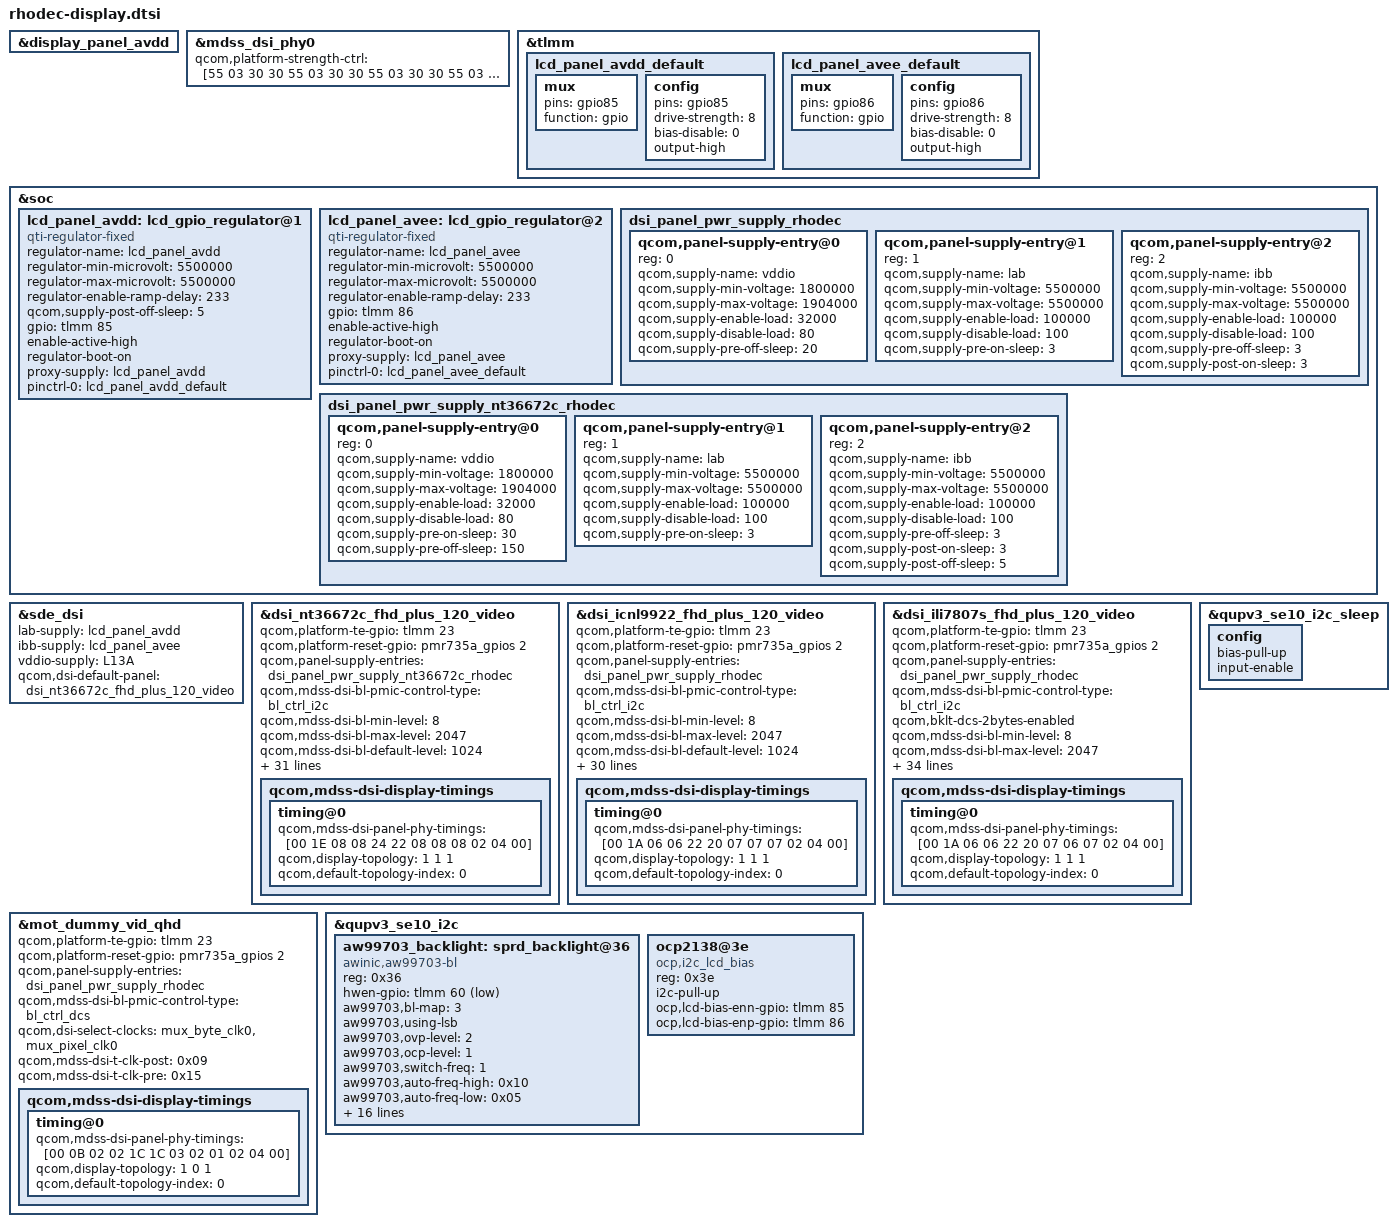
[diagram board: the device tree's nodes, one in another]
#include "dsi-panel-mot-dummy-qhd-video.dtsi"
#include "dsi-panel-mot-tianma-nt36672c-645-1080x2400-video.dtsi"
#include "dsi-panel-mot-txd-ili7807s-645-1080x2400-video.dtsi"
#include "dsi-panel-mot-tianma-icnl9922-645-1080x2400-video.dtsi"

&display_panel_avdd {
	/delete-property/ gpio;
	/delete-property/ pinctrl-0;
};

&mdss_dsi_phy0 {
	qcom,platform-strength-ctrl = [55 03 30 30
				55 03 30 30
				55 03 30 30
				55 03 30 30
				55 00 30 30];
};

&tlmm {
	lcd_panel_avdd_default: lcd_panel_avdd_default {
		mux {
			pins = "gpio85";
			function = "gpio";
		};

		config {
			pins = "gpio85";
			drive-strength = <8>;
			bias-disable = <0>;
			output-high;
		};
	};

	lcd_panel_avee_default: lcd_panel_avee_default {
		mux {
			pins = "gpio86";
			function = "gpio";
		};

		config {
			pins = "gpio86";
			drive-strength = <8>;
			bias-disable = <0>;
			output-high;
		};
	};
};

&soc {
	lcd_panel_avdd: lcd_gpio_regulator@1 {
		compatible = "qti-regulator-fixed";
		regulator-name = "lcd_panel_avdd";
		regulator-min-microvolt = <5500000>;
		regulator-max-microvolt = <5500000>;
		regulator-enable-ramp-delay = <233>;
		qcom,supply-post-off-sleep = <5>;
		gpio = <&tlmm 85 0>;
		enable-active-high;
		regulator-boot-on;
		proxy-supply = <&lcd_panel_avdd>;
		pinctrl-names = "default";
		pinctrl-0 = <&lcd_panel_avdd_default>;
	};

	lcd_panel_avee: lcd_gpio_regulator@2 {
		compatible = "qti-regulator-fixed";
		regulator-name = "lcd_panel_avee";
		regulator-min-microvolt = <5500000>;
		regulator-max-microvolt = <5500000>;
		regulator-enable-ramp-delay = <233>;
		gpio = <&tlmm 86 0>;
		enable-active-high;
		regulator-boot-on;
		proxy-supply = <&lcd_panel_avee>;
		pinctrl-names = "default";
		pinctrl-0 = <&lcd_panel_avee_default>;
	};
};

&sde_dsi {
	/delete-property/ lab-supply;
	/delete-property/ ibb-supply;
	/delete-property/ vddio-supply;
	/delete-property/ qcom,dsi-default-panel;
	/delete-property/ avdd-supply;

	lab-supply = <&lcd_panel_avdd>;
	ibb-supply = <&lcd_panel_avee>;
	vddio-supply = <&L13A>;

	qcom,dsi-default-panel = <&dsi_nt36672c_fhd_plus_120_video>;
};

&soc {
	dsi_panel_pwr_supply_rhodec: dsi_panel_pwr_supply_rhodec{
		#address-cells = <1>;
		#size-cells = <0>;

		qcom,panel-supply-entry@0 {
			reg = <0>;
			qcom,supply-name = "vddio";
			qcom,supply-min-voltage = <1800000>;
			qcom,supply-max-voltage = <1904000>;
			qcom,supply-enable-load = <32000>;
			qcom,supply-disable-load = <80>;
			qcom,supply-pre-off-sleep = <20>;
		};

		qcom,panel-supply-entry@1 {
			reg = <1>;
			qcom,supply-name = "lab";
			qcom,supply-min-voltage = <5500000>;
			qcom,supply-max-voltage = <5500000>;
			qcom,supply-enable-load = <100000>;
			qcom,supply-disable-load = <100>;
			qcom,supply-pre-on-sleep = <3>;
		};

		qcom,panel-supply-entry@2 {
			reg = <2>;
			qcom,supply-name = "ibb";
			qcom,supply-min-voltage = <5500000>;
			qcom,supply-max-voltage = <5500000>;
			qcom,supply-enable-load = <100000>;
			qcom,supply-disable-load = <100>;
			qcom,supply-pre-off-sleep = <3>;
			qcom,supply-post-on-sleep = <3>;
		};

	};
};

&soc {
	dsi_panel_pwr_supply_nt36672c_rhodec: dsi_panel_pwr_supply_nt36672c_rhodec{
		#address-cells = <1>;
		#size-cells = <0>;

		qcom,panel-supply-entry@0 {
			reg = <0>;
			qcom,supply-name = "vddio";
			qcom,supply-min-voltage = <1800000>;
			qcom,supply-max-voltage = <1904000>;
			qcom,supply-enable-load = <32000>;
			qcom,supply-disable-load = <80>;
			qcom,supply-pre-on-sleep = <30>;
			qcom,supply-pre-off-sleep = <150>;
		};

		qcom,panel-supply-entry@1 {
			reg = <1>;
			qcom,supply-name = "lab";
			qcom,supply-min-voltage = <5500000>;
			qcom,supply-max-voltage = <5500000>;
			qcom,supply-enable-load = <100000>;
			qcom,supply-disable-load = <100>;
			qcom,supply-pre-on-sleep = <3>;
		};

		qcom,panel-supply-entry@2 {
			reg = <2>;
			qcom,supply-name = "ibb";
			qcom,supply-min-voltage = <5500000>;
			qcom,supply-max-voltage = <5500000>;
			qcom,supply-enable-load = <100000>;
			qcom,supply-disable-load = <100>;
			qcom,supply-pre-off-sleep = <3>;
			qcom,supply-post-on-sleep = <3>;
			qcom,supply-post-off-sleep = <5>;
		};

	};
};

&dsi_nt36672c_fhd_plus_120_video {
	qcom,platform-te-gpio = <&tlmm 23 0>;
	qcom,platform-reset-gpio = <&pmr735a_gpios 2 0>;

	qcom,panel-supply-entries = <&dsi_panel_pwr_supply_nt36672c_rhodec>;
	qcom,mdss-dsi-bl-pmic-control-type = "bl_ctrl_i2c";
	qcom,mdss-dsi-bl-min-level = <8>;
	qcom,mdss-dsi-bl-max-level = <2047>;
	qcom,mdss-dsi-bl-default-level = <1024>;
	qcom,mdss-brightness-max-level = <2047>;
	qcom,mdss-dsi-no-panel-on-read-support;
	qcom,mdss-dsi-panel-supplier = "tm";

	qcom,esd-check-enabled;
	qcom,mdss-dsi-panel-status-check-mode = "reg_read";
	qcom,mdss-dsi-panel-status-command = [06 01 00 01 00 00 01 0a];
	qcom,mdss-dsi-panel-status-command-state = "dsi_lp_mode";
	qcom,mdss-dsi-panel-status-value = <0x9c>;
	qcom,mdss-dsi-panel-on-check-value = <0x9c>;
	qcom,mdss-dsi-panel-status-read-length = <1>;

	qcom,tp_state_check_enable;

	qcom,dsi-supported-dfps-list = <120 90 60>;
	qcom,mdss-dsi-pan-enable-dynamic-fps;
	qcom,mdss-dsi-pan-fps-update = "dfps_immediate_porch_mode_vfp";

	qcom,mdss-dsi-hbm-on-command = [39 01 00 00 00 00 03 51 07 FF];
	qcom,mdss-dsi-hbm-on-command-state =  "dsi_lp_mode";
	qcom,mdss-dsi-hbm-off-command = [39 01 00 00 00 00 03 51 06 66];
	qcom,mdss-dsi-hbm-off-command-state =  "dsi_lp_mode";
	qcom,mdss-dsi-hbm-type = "lcd-dcs-wled";

	qcom,dsi-select-clocks = "mux_byte_clk0", "mux_pixel_clk0";
	qcom,mdss-dsi-t-clk-post = <0x0D>;
	qcom,mdss-dsi-t-clk-pre = <0x34>;
	qcom,mdss-dsi-display-timings {
		timing@0 {
			qcom,mdss-dsi-panel-phy-timings = [00 1E 08 08 24 22 08 08 08 02 04 00];
			qcom,display-topology = <1 1 1>;
			qcom,default-topology-index = <0>;
		};
	};
};



&dsi_icnl9922_fhd_plus_120_video {
        qcom,platform-te-gpio = <&tlmm 23 0>;
        qcom,platform-reset-gpio = <&pmr735a_gpios 2 0>;

        qcom,panel-supply-entries = <&dsi_panel_pwr_supply_rhodec>;
        qcom,mdss-dsi-bl-pmic-control-type = "bl_ctrl_i2c";
        qcom,mdss-dsi-bl-min-level = <8>;
        qcom,mdss-dsi-bl-max-level = <2047>;
        qcom,mdss-dsi-bl-default-level = <1024>;
        qcom,mdss-brightness-max-level = <2047>;
        qcom,mdss-dsi-no-panel-on-read-support;

        qcom,esd-check-enabled;
        qcom,mdss-dsi-panel-status-check-mode = "reg_read";
        qcom,mdss-dsi-panel-status-command = [06 01 00 01 00 00 01 0a];
        qcom,mdss-dsi-panel-status-command-state = "dsi_lp_mode";
        qcom,mdss-dsi-panel-status-value = <0x9c>;
        qcom,mdss-dsi-panel-on-check-value = <0x9c>;
        qcom,mdss-dsi-panel-status-read-length = <1>;

        qcom,tp_state_check_enable;

        qcom,dsi-supported-dfps-list = <120 90 60>;
        qcom,mdss-dsi-pan-enable-dynamic-fps;
        qcom,mdss-dsi-pan-fps-update = "dfps_immediate_porch_mode_vfp";

        qcom,mdss-dsi-hbm-on-command = [15 01 00 00 00 00 02 51 FF];
        qcom,mdss-dsi-hbm-on-command-state =  "dsi_lp_mode";
        qcom,mdss-dsi-hbm-off-command = [15 01 00 00 00 00 02 51 CC];
        qcom,mdss-dsi-hbm-off-command-state =  "dsi_lp_mode";
        qcom,mdss-dsi-hbm-type = "lcd-dcs-wled";

        qcom,dsi-select-clocks = "mux_byte_clk0", "mux_pixel_clk0";
        qcom,mdss-dsi-t-clk-post = <0x0E>;
        qcom,mdss-dsi-t-clk-pre = <0x39>;
        qcom,mdss-dsi-display-timings {
                timing@0 {
                        qcom,mdss-dsi-panel-phy-timings = [00 1A 06 06 22 20 07 07 07 02 04 00];
                        qcom,display-topology = <1 1 1>;
                        qcom,default-topology-index = <0>;
                };
        };
};

&dsi_ili7807s_fhd_plus_120_video {
	qcom,platform-te-gpio = <&tlmm 23 0>;
	qcom,platform-reset-gpio = <&pmr735a_gpios 2 0>;

	qcom,panel-supply-entries = <&dsi_panel_pwr_supply_rhodec>;
	qcom,mdss-dsi-bl-pmic-control-type = "bl_ctrl_i2c";
	qcom,bklt-dcs-2bytes-enabled;

	qcom,mdss-dsi-bl-min-level = <8>;
	qcom,mdss-dsi-bl-max-level = <2047>;
	qcom,mdss-dsi-bl-default-level = <1024>;
	qcom,mdss-brightness-max-level = <2047>;

	qcom,esd-check-enabled;
	qcom,mdss-dsi-panel-status-check-mode = "reg_read";
	qcom,mdss-dsi-panel-status-command = [06 01 00 01 00 00 01 0a];
	qcom,mdss-dsi-panel-status-command-state = "dsi_lp_mode";
	qcom,mdss-dsi-panel-status-value = <0x9c>;
	qcom,mdss-dsi-panel-on-check-value = <0x9c>;
	qcom,mdss-dsi-panel-status-read-length = <1>;
	qcom,mdss-dsi-no-panel-on-read-support;
	qcom,mdss-dsi-panel-supplier = "txd";

	qcom,mdss-dsi-hbm-on-command = [39 01 00 00 00 00 03 51 07 FF];
	qcom,mdss-dsi-hbm-on-command-state =  "dsi_lp_mode";
	qcom,mdss-dsi-hbm-off-command = [39 01 00 00 00 00 03 51 06 66];
	qcom,mdss-dsi-hbm-off-command-state =  "dsi_lp_mode";
        qcom,mdss-dsi-hbm-type = "lcd-dcs-wled";

	qcom,suspend-ulps-enabled;

	qcom,tp_state_check_enable;
	qcom,platform-need-execute-shutdown;

	qcom,mdss-dsi-pan-enable-dynamic-fps;
	qcom,mdss-dsi-pan-fps-update = "dfps_immediate_porch_mode_vfp";
	qcom,dsi-supported-dfps-list = <120 90 60>;

	qcom,dsi-select-clocks = "mux_byte_clk0", "mux_pixel_clk0";
	qcom,mdss-dsi-t-clk-post = <0x0C>;
	qcom,mdss-dsi-t-clk-pre = <0x2F>;
	qcom,mdss-dsi-display-timings {
		timing@0 {
			qcom,mdss-dsi-panel-phy-timings = [00 1A 06 06 22 20 07
				06 07 02 04 00];
			qcom,display-topology = <1 1 1>;
			qcom,default-topology-index = <0>;
		};
	};
};

&mot_dummy_vid_qhd {
	qcom,platform-te-gpio = <&tlmm 23 0>;
	qcom,platform-reset-gpio = <&pmr735a_gpios 2 0>;

	qcom,panel-supply-entries = <&dsi_panel_pwr_supply_rhodec>;

	qcom,mdss-dsi-bl-pmic-control-type = "bl_ctrl_dcs";

	qcom,dsi-select-clocks = "mux_byte_clk0", "mux_pixel_clk0";
	qcom,mdss-dsi-t-clk-post = <0x09>;
	qcom,mdss-dsi-t-clk-pre = <0x15>;
	qcom,mdss-dsi-display-timings {
		timing@0 {
			qcom,mdss-dsi-panel-phy-timings = [00 0B 02 02 1C 1C 03
							02 01 02 04 00];
			qcom,display-topology = <1 0 1>;
			qcom,default-topology-index = <0>;
		};
	};
};

&qupv3_se10_i2c {
	status = "ok";

	aw99703_backlight: sprd_backlight@36{
		compatible = "awinic,aw99703-bl","sm-sm5350";
		reg = <0x36>;
		hwen-gpio = <&tlmm 60 1>;
                aw99703,bl-map = <3>; /* brightness map level 1:256,2:1024,3:2048 */
                aw99703,using-lsb;
                aw99703,ovp-level = <2>; /* 0:17.5V, 1:24V, 2:31V, 3:38V, 4:41.5V */
                aw99703,ocp-level = <1>; /* 0:0.9A, 1:1.8A, 2:2.7A, 3:3.4A */
                aw99703,switch-freq = <1>; /* 1000kHz(default) */
                aw99703,auto-freq-high = <0x10>;
                aw99703,auto-freq-low = <0x05>;
                aw99703,bl-fscal-led = <0x17>; /* 24.8mA */
                aw99703,bl-channel = <3>;
                aw99703,turn-on-ramp = <0x00>; /* 512us */
                aw99703,turn-off-ramp = <0x04>; /* 8ms */
                aw99703,pwm-trans-dim = <0>; /* 2ms */
                aw99703,i2c-trans-dim = <1>; /* 128ms */
                aw99703,pwm-mode = <1>; /* 1 pwm enable,0 PWM disable */
                aw99703,map-type = <0>; /* 0 exponential, 4 linear */
                aw99703,work-mode = <1>; /* backlight */
		aw99703,default-brightness = <1810>;

		status = "okay";
		pwm-cfg = <0x0F>;
		boost-ctl = <0x03>;
		ctl-bank-en = <0x02>;
		full-scale-current = <0x17>;
		map-mode = <0>; /* 0 exponential, 1 linear */
		sm5350,default-brightness = <1810>;
	};

             ocp2138@3e {
                       compatible = "ocp,i2c_lcd_bias";
                       reg = <0x3e>;
                       i2c-pull-up;
                       ocp,lcd-bias-enn-gpio = <&tlmm 85 0>;
                       ocp,lcd-bias-enp-gpio = <&tlmm 86 0>;
        };
};

&qupv3_se10_i2c_sleep {
    config {
        /delete-property/ bias-disable;
        bias-pull-up;
        input-enable;
    };
};
